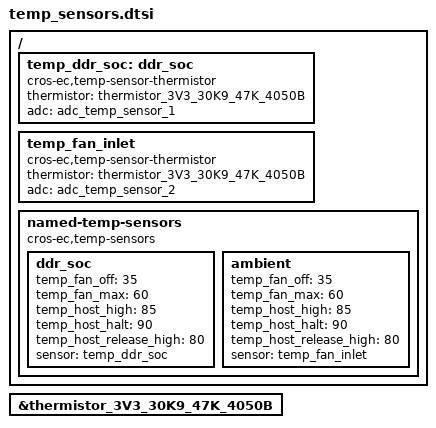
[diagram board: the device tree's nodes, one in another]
/* Copyright 2024 The ChromiumOS Authors
 * Use of this source code is governed by a BSD-style license that can be
 * found in the LICENSE file.
 */
 #include <cros/thermistor/thermistor.dtsi>

 / {
	 temp_ddr_soc: ddr_soc {
		 compatible = "cros-ec,temp-sensor-thermistor";
		 thermistor = <&thermistor_3V3_30K9_47K_4050B>;
		 adc = <&adc_temp_sensor_1>;
	 };
	 temp_fan_inlet: temp_fan_inlet {
		compatible = "cros-ec,temp-sensor-thermistor";
		thermistor = <&thermistor_3V3_30K9_47K_4050B>;
		adc = <&adc_temp_sensor_2>;
	};

	named-temp-sensors {
		compatible = "cros-ec,temp-sensors";
		ddr_soc {
			temp_fan_off = <35>;
			temp_fan_max = <60>;
			temp_host_high = <85>;
			temp_host_halt = <90>;
			temp_host_release_high = <80>;
			sensor = <&temp_ddr_soc>;
		};

		ambient {
			temp_fan_off = <35>;
			temp_fan_max = <60>;
			temp_host_high = <85>;
			temp_host_halt = <90>;
			temp_host_release_high = <80>;
			sensor = <&temp_fan_inlet>;
		};
	};
};

&thermistor_3V3_30K9_47K_4050B {
	status = "okay";
};
